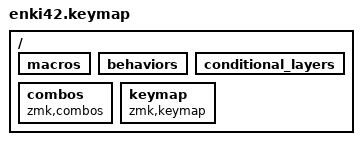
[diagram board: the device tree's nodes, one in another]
#include <behaviors.dtsi>
#include <dt-bindings/zmk/keys.h>
#include <dt-bindings/zmk/bt.h>
#include <dt-bindings/zmk/outputs.h>

#define ZMK_POINTING_DEFAULT_MOVE_VAL 2000  // default: 600	
#define ZMK_POINTING_DEFAULT_SCRL_VAL 60    // default: 10		
#include <dt-bindings/zmk/pointing.h>

#include "helpers/combos.keymap"
#include "os/define.keymap"

#include "settings/press.keymap"
#include "settings/mouse.keymap"

#include "settings/nice_view.keymap"

/ {
        macros {
                #include "os/macros.keymap"
        };

        behaviors {
                #include "os/tap_dance.keymap"
        };

        conditional_layers {
                // compatible = "zmk,conditional-layers";
                // #include "os/conditional.keymap"
        };

        combos {
                compatible = "zmk,combos";
                #include "os/combos.keymap"
        };

        keymap {
                compatible = "zmk,keymap";
                #include "keymap/0_base.keymap"
                #include "keymap/1_lower.keymap"
                #include "keymap/2_raise.keymap"
                #include "keymap/3_number.keymap"
                #include "keymap/4_extra.keymap"
                #include "keymap/5_uber.keymap"
                #include "keymap/6_player.keymap"
        };
};
